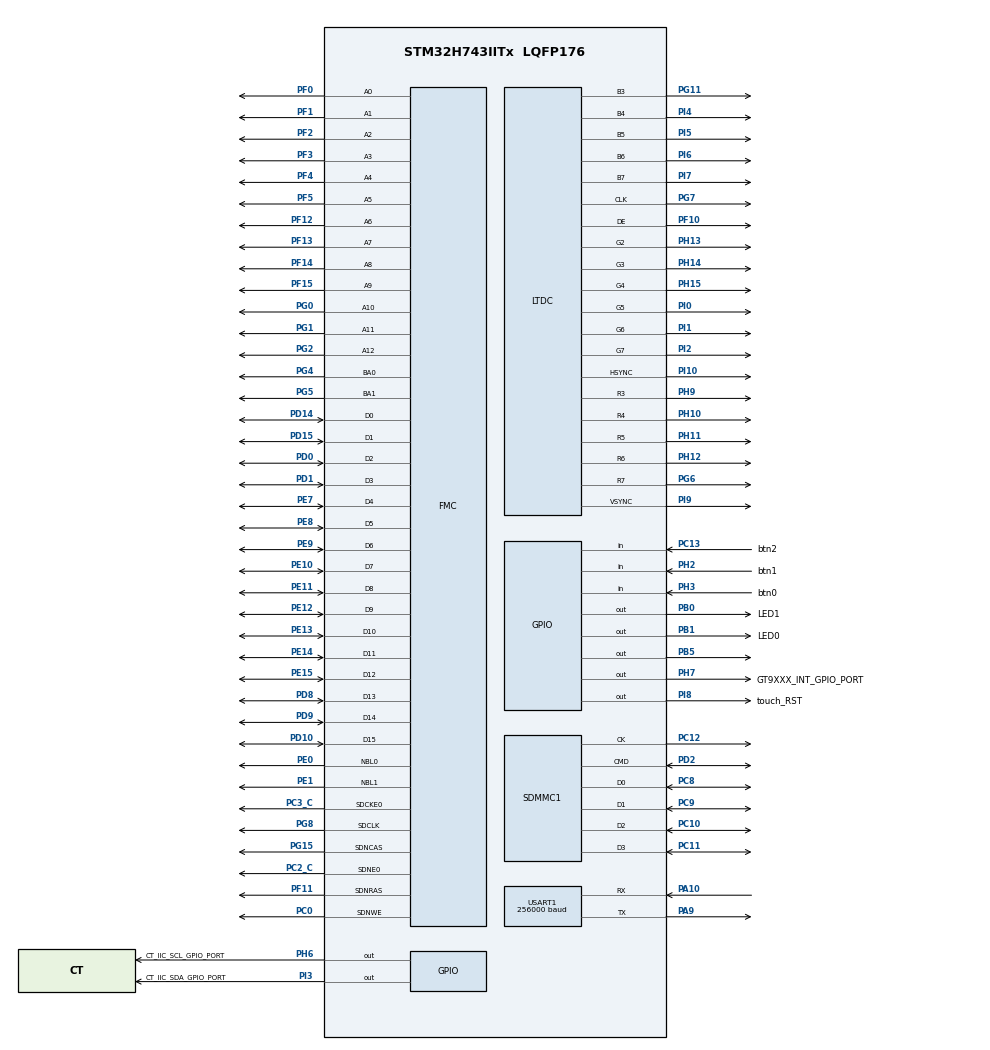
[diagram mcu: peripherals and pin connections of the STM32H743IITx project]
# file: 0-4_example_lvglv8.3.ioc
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CORTEX_M7.CPU_ICache=Disabled
CORTEX_M7.MPU_Control=__NULL
CORTEX_M7.default_mode_Activation=1
DMA2D.ColorMode=DMA2D_OUTPUT_RGB565
Dma.Request0=USART1_RX
Dma.Request1=USART1_TX
Dma.USART1_RX.0.Direction=DMA_PERIPH_TO_MEMORY
Dma.USART1_RX.0.EventEnable=DISABLE
Dma.USART1_RX.0.FIFOMode=DMA_FIFOMODE_DISABLE
Dma.USART1_RX.0.Instance=DMA1_Stream0
Dma.USART1_RX.0.MemDataAlignment=DMA_MDATAALIGN_BYTE
Dma.USART1_RX.0.MemInc=DMA_MINC_ENABLE
Dma.USART1_RX.0.Mode=DMA_NORMAL
Dma.USART1_RX.0.PeriphDataAlignment=DMA_PDATAALIGN_BYTE
Dma.USART1_RX.0.PeriphInc=DMA_PINC_DISABLE
Dma.USART1_RX.0.Polarity=HAL_DMAMUX_REQ_GEN_RISING
Dma.USART1_RX.0.Priority=DMA_PRIORITY_LOW
Dma.USART1_RX.0.RequestNumber=1
Dma.USART1_RX.0.SignalID=NONE
Dma.USART1_RX.0.SyncEnable=DISABLE
Dma.USART1_RX.0.SyncPolarity=HAL_DMAMUX_SYNC_NO_EVENT
Dma.USART1_RX.0.SyncRequestNumber=1
Dma.USART1_RX.0.SyncSignalID=NONE
Dma.USART1_TX.1.Direction=DMA_MEMORY_TO_PERIPH
Dma.USART1_TX.1.EventEnable=DISABLE
Dma.USART1_TX.1.FIFOMode=DMA_FIFOMODE_DISABLE
Dma.USART1_TX.1.Instance=DMA1_Stream1
Dma.USART1_TX.1.MemDataAlignment=DMA_MDATAALIGN_BYTE
Dma.USART1_TX.1.MemInc=DMA_MINC_ENABLE
Dma.USART1_TX.1.Mode=DMA_NORMAL
Dma.USART1_TX.1.PeriphDataAlignment=DMA_PDATAALIGN_BYTE
Dma.USART1_TX.1.PeriphInc=DMA_PINC_DISABLE
Dma.USART1_TX.1.Polarity=HAL_DMAMUX_REQ_GEN_RISING
Dma.USART1_TX.1.Priority=DMA_PRIORITY_LOW
Dma.USART1_TX.1.RequestNumber=1
Dma.USART1_TX.1.SignalID=NONE
Dma.USART1_TX.1.SyncEnable=DISABLE
Dma.USART1_TX.1.SyncPolarity=HAL_DMAMUX_SYNC_NO_EVENT
Dma.USART1_TX.1.SyncRequestNumber=1
Dma.USART1_TX.1.SyncSignalID=NONE
FATFS.USE_DMA_CODE_SD=1
FATFS._CODE_PAGE=936
FATFS._FS_EXFAT=1
FATFS._FS_RPATH=2
FATFS._LFN_UNICODE=1
FATFS._MAX_SS=4096
FATFS._USE_LFN=3
FATFS._USE_TRIM=1
FMC.CASLatency1=FMC_SDRAM_CAS_LATENCY_2
FMC.ColumnBitsNumber1=FMC_SDRAM_COLUMN_BITS_NUM_9
FMC.ExitSelfRefreshDelay1=8
FMC.LoadToActiveDelay1=2
FMC.RCDDelay1=2
FMC.RPDelay1=2
FMC.RPDelay2=2
FMC.ReadBurst1=FMC_SDRAM_RBURST_ENABLE
FMC.ReadBurst2=FMC_SDRAM_RBURST_ENABLE
FMC.ReadPipeDelay1=FMC_SDRAM_RPIPE_DELAY_1
FMC.ReadPipeDelay2=FMC_SDRAM_RPIPE_DELAY_1
FMC.RowCycleDelay1=6
FMC.RowCycleDelay2=6
FMC.SDClockPeriod1=FMC_SDRAM_CLOCK_PERIOD_2
FMC.SDClockPeriod2=FMC_SDRAM_CLOCK_PERIOD_2
FMC.SelfRefreshTime1=6
FMC.WriteRecoveryTime1=4
LTDC.ActiveW=800
LTDC.Alpha0_L0=0
LTDC.Alpha0_L1=0
LTDC.Alpha_L0=255
LTDC.Alpha_L1=255
LTDC.BlendingFactor1_L0=LTDC_BLENDING_FACTOR1_CA
LTDC.BlendingFactor1_L1=LTDC_BLENDING_FACTOR1_CA
LTDC.BlendingFactor2_L0=LTDC_BLENDING_FACTOR2_CA
LTDC.BlendingFactor2_L1=LTDC_BLENDING_FACTOR2_CA
LTDC.Blue=0
LTDC.Blue_L0=0
LTDC.Blue_L1=0
LTDC.FBStartAdress_L0=Layer0_Buffer
LTDC.FBStartAdress_L1=Layer1_Buffer
LTDC.Green=0
LTDC.Green_L0=0
LTDC.Green_L1=0
LTDC.HBP=88
LTDC.HFP=40
LTDC.HSync=48
LTDC.ImageHeight_L0=480
LTDC.ImageHeight_L1=480
LTDC.ImageWidth_L0=800
LTDC.Layers=0
LTDC.PCPolarity=LTDC_PCPOLARITY_IPC
LTDC.PixelFormat_L0=LTDC_PIXEL_FORMAT_RGB565
LTDC.Red=0
LTDC.Red_L0=0
LTDC.Red_L1=0
LTDC.VBP=32
LTDC.VFP=13
LTDC.VSync=3
LTDC.WindowX1_L0=800
LTDC.WindowX1_L1=800
LTDC.WindowY1_L0=480
LTDC.WindowY1_L1=480
Mcu.Family=STM32H7
Mcu.Name=STM32H743IITx
Mcu.Package=LQFP176
NVIC.DMA1_Stream0_IRQn=true\:0\:0\:false\:false\:true\:false\:true\:true
NVIC.DMA1_Stream1_IRQn=true\:0\:0\:false\:false\:true\:false\:true\:true
NVIC.DMA2D_IRQn=true\:1\:0\:true\:true\:true\:1\:true\:true\:true
NVIC.FMC_IRQn=true\:0\:0\:false\:false\:true\:true\:true\:true
NVIC.LTDC_ER_IRQn=true\:0\:0\:false\:false\:true\:true\:true\:true
NVIC.LTDC_IRQn=true\:0\:0\:false\:false\:true\:true\:true\:true
NVIC.PriorityGroup=NVIC_PRIORITYGROUP_4
NVIC.SDMMC1_IRQn=true\:1\:0\:true\:false\:true\:true\:true\:true
NVIC.TIM6_DAC_IRQn=true\:0\:0\:false\:false\:true\:true\:true\:true
NVIC.USART1_IRQn=true\:2\:0\:true\:false\:true\:true\:true\:true
PA10.Mode=Asynchronous
PA10.Signal=USART1_RX
PA13\ (JTMS/SWDIO).Mode=Serial_Wire
PA13\ (JTMS/SWDIO).Signal=DEBUG_JTMS-SWDIO
PA14\ (JTCK/SWCLK).Mode=Serial_Wire
PA14\ (JTCK/SWCLK).Signal=DEBUG_JTCK-SWCLK
PA9.Mode=Asynchronous
PA9.Signal=USART1_TX
PB0.GPIO_Label=LED1
PB0.GPIO_PuPd=GPIO_PULLUP
PB0.GPIO_Speed=GPIO_SPEED_FREQ_HIGH
PB0.PinState=GPIO_PIN_SET
PB0.Signal=GPIO_Output
PB1.GPIO_Label=LED0
PB1.GPIO_PuPd=GPIO_NOPULL
PB1.GPIO_Speed=GPIO_SPEED_FREQ_HIGH
PB1.Signal=GPIO_Output
PB5.PinState=GPIO_PIN_SET
PB5.Signal=GPIO_Output
PC0.Signal=FMC_SDNWE
PC10.Mode=SD_4_bits_Wide_bus
PC10.Signal=SDMMC1_D2
PC11.Mode=SD_4_bits_Wide_bus
PC11.Signal=SDMMC1_D3
PC12.Mode=SD_4_bits_Wide_bus
PC12.Signal=SDMMC1_CK
PC13.GPIO_Label=btn2
PC13.GPIO_PuPd=GPIO_PULLUP
PC13.Signal=GPIO_Input
PC14-OSC32_IN\ (OSC32_IN).Mode=LSE-External-Oscillator
PC14-OSC32_IN\ (OSC32_IN).Signal=RCC_OSC32_IN
PC15-OSC32_OUT\ (OSC32_OUT).Mode=LSE-External-Oscillator
PC15-OSC32_OUT\ (OSC32_OUT).Signal=RCC_OSC32_OUT
PC2_C.Mode=SdramChipSelect1_1
PC2_C.Signal=FMC_SDNE0
PC3_C.Mode=SdramChipSelect1_1
PC3_C.Signal=FMC_SDCKE0
PC8.Mode=SD_4_bits_Wide_bus
PC8.Signal=SDMMC1_D0
PC9.Mode=SD_4_bits_Wide_bus
PC9.Signal=SDMMC1_D1
PD0.Signal=FMC_D2_DA2
PD1.Signal=FMC_D3_DA3
PD10.Signal=FMC_D15_DA15
PD14.Signal=FMC_D0_DA0
PD15.Signal=FMC_D1_DA1
PD2.Mode=SD_4_bits_Wide_bus
PD2.Signal=SDMMC1_CMD
PD8.Signal=FMC_D13_DA13
PD9.Signal=FMC_D14_DA14
PE0.Signal=FMC_NBL0
PE1.Signal=FMC_NBL1
PE10.Signal=FMC_D7_DA7
PE11.Signal=FMC_D8_DA8
PE12.Signal=FMC_D9_DA9
PE13.Signal=FMC_D10_DA10
PE14.Signal=FMC_D11_DA11
PE15.Signal=FMC_D12_DA12
PE7.Signal=FMC_D4_DA4
PE8.Signal=FMC_D5_DA5
PE9.Signal=FMC_D6_DA6
PF0.Signal=FMC_A0
PF1.Signal=FMC_A1
PF10.GPIO_Speed=GPIO_SPEED_FREQ_VERY_HIGH
PF10.Mode=RGB565
PF10.Signal=LTDC_DE
PF11.Signal=FMC_SDNRAS
PF12.Signal=FMC_A6
PF13.Signal=FMC_A7
PF14.Signal=FMC_A8
PF15.Signal=FMC_A9
PF2.Signal=FMC_A2
PF3.Signal=FMC_A3
PF4.Signal=FMC_A4
PF5.Signal=FMC_A5
PG0.Signal=FMC_A10
PG1.Signal=FMC_A11
PG11.GPIO_Speed=GPIO_SPEED_FREQ_VERY_HIGH
PG11.Mode=RGB565
PG11.Signal=LTDC_B3
PG15.Signal=FMC_SDNCAS
PG2.Signal=FMC_A12
PG4.Signal=FMC_A14_BA0
PG5.Signal=FMC_A15_BA1
PG6.GPIO_Speed=GPIO_SPEED_FREQ_VERY_HIGH
PG6.Mode=RGB565
PG6.Signal=LTDC_R7
PG7.GPIO_Speed=GPIO_SPEED_FREQ_VERY_HIGH
PG7.Mode=RGB565
PG7.Signal=LTDC_CLK
PG8.Signal=FMC_SDCLK
PH0-OSC_IN\ (PH0).Mode=HSE-External-Oscillator
PH0-OSC_IN\ (PH0).Signal=RCC_OSC_IN
PH1-OSC_OUT\ (PH1).Mode=HSE-External-Oscillator
PH1-OSC_OUT\ (PH1).Signal=RCC_OSC_OUT
PH10.GPIO_Speed=GPIO_SPEED_FREQ_VERY_HIGH
PH10.Mode=RGB565
PH10.Signal=LTDC_R4
PH11.GPIO_Speed=GPIO_SPEED_FREQ_VERY_HIGH
PH11.Mode=RGB565
PH11.Signal=LTDC_R5
PH12.GPIO_Speed=GPIO_SPEED_FREQ_VERY_HIGH
PH12.Mode=RGB565
PH12.Signal=LTDC_R6
PH13.GPIO_Speed=GPIO_SPEED_FREQ_VERY_HIGH
PH13.Mode=RGB565
PH13.Signal=LTDC_G2
PH14.GPIO_Speed=GPIO_SPEED_FREQ_VERY_HIGH
PH14.Mode=RGB565
PH14.Signal=LTDC_G3
PH15.GPIO_Speed=GPIO_SPEED_FREQ_VERY_HIGH
PH15.Mode=RGB565
PH15.Signal=LTDC_G4
PH2.GPIO_Label=btn1
PH2.GPIO_PuPd=GPIO_PULLUP
PH2.Signal=GPIO_Input
PH3.GPIO_Label=btn0
PH3.GPIO_PuPd=GPIO_PULLUP
PH3.Signal=GPIO_Input
PH6.GPIO_Label=CT_IIC_SCL_GPIO_PORT
PH6.GPIO_ModeDefaultOutputPP=GPIO_MODE_OUTPUT_PP
PH6.GPIO_PuPd=GPIO_PULLUP
PH6.GPIO_Speed=GPIO_SPEED_FREQ_HIGH
PH6.PinState=GPIO_PIN_RESET
PH6.Signal=GPIO_Output
PH7.GPIO_Label=GT9XXX_INT_GPIO_PORT
PH7.GPIO_Speed=GPIO_SPEED_FREQ_HIGH
PH7.Signal=GPIO_Output
PH9.GPIO_Speed=GPIO_SPEED_FREQ_VERY_HIGH
PH9.Mode=RGB565
PH9.Signal=LTDC_R3
PI0.GPIO_Speed=GPIO_SPEED_FREQ_VERY_HIGH
PI0.Mode=RGB565
PI0.Signal=LTDC_G5
PI1.GPIO_Speed=GPIO_SPEED_FREQ_VERY_HIGH
PI1.Mode=RGB565
PI1.Signal=LTDC_G6
PI10.GPIO_Speed=GPIO_SPEED_FREQ_VERY_HIGH
PI10.Mode=RGB565
PI10.Signal=LTDC_HSYNC
PI2.GPIO_Speed=GPIO_SPEED_FREQ_VERY_HIGH
PI2.Mode=RGB565
PI2.Signal=LTDC_G7
PI3.GPIO_Label=CT_IIC_SDA_GPIO_PORT
PI3.GPIO_PuPd=GPIO_PULLUP
PI3.GPIO_Speed=GPIO_SPEED_FREQ_HIGH
PI3.PinState=GPIO_PIN_RESET
PI3.Signal=GPIO_Output
PI4.GPIO_Speed=GPIO_SPEED_FREQ_VERY_HIGH
PI4.Mode=RGB565
PI4.Signal=LTDC_B4
PI5.GPIO_Speed=GPIO_SPEED_FREQ_VERY_HIGH
PI5.Mode=RGB565
PI5.Signal=LTDC_B5
PI6.GPIO_Speed=GPIO_SPEED_FREQ_VERY_HIGH
PI6.Mode=RGB565
PI6.Signal=LTDC_B6
PI7.GPIO_Speed=GPIO_SPEED_FREQ_VERY_HIGH
PI7.Mode=RGB565
PI7.Signal=LTDC_B7
PI8.GPIO_Label=touch_RST
PI8.Signal=GPIO_Output
PI9.GPIO_Speed=GPIO_SPEED_FREQ_VERY_HIGH
PI9.Mode=RGB565
PI9.Signal=LTDC_VSYNC
ProjectManager.HeapSize=0x1200
ProjectManager.StackSize=0x1200
ProjectManager.TargetToolchain=STM32CubeIDE
RCC.ADCFreq_Value=480000000
RCC.APB1Freq_Value=120000000
RCC.APB2Freq_Value=120000000
RCC.APB3Freq_Value=120000000
RCC.APB4Freq_Value=120000000
RCC.CortexFreq_Value=480000000
RCC.D1PPRE=RCC_APB3_DIV2
RCC.D2PPRE1=RCC_APB1_DIV2
RCC.D2PPRE2=RCC_APB2_DIV2
RCC.D3PPRE=RCC_APB4_DIV2
RCC.DIVM1=5
RCC.DIVM2=5
RCC.DIVM3=25
RCC.DIVN1=192
RCC.DIVN2=192
RCC.DIVN3=396
RCC.DIVQ1=4
RCC.DIVQ2=4
RCC.DIVR2=4
RCC.DIVR3=9
RCC.HCLKFreq_Value=240000000
RCC.HPRE=RCC_HCLK_DIV2
RCC.PLLSourceVirtual=RCC_PLLSOURCE_HSE
RCC.RTCClockSelection=RCC_RTCCLKSOURCE_LSE
RCC.SYSCLKFreq_VALUE=480000000
RCC.SYSCLKSource=RCC_SYSCLKSOURCE_PLLCLK
RCC.USBFreq_Value=240000000
RTC.Date=3
RTC.Format=RTC_FORMAT_BIN
RTC.Hours=3
RTC.Minutes=3
RTC.Seconds=3
RTC.Year=3
SDMMC1.ClockDiv=8
SH.FMC_A0.0=FMC_A0,13b-sda1
SH.FMC_A1.0=FMC_A1,13b-sda1
SH.FMC_A10.0=FMC_A10,13b-sda1
SH.FMC_A11.0=FMC_A11,13b-sda1
SH.FMC_A12.0=FMC_A12,13b-sda1
SH.FMC_A14_BA0.0=FMC_BA0,FourSdramBanks1
SH.FMC_A15_BA1.0=FMC_BA1,FourSdramBanks1
SH.FMC_A2.0=FMC_A2,13b-sda1
SH.FMC_A3.0=FMC_A3,13b-sda1
SH.FMC_A4.0=FMC_A4,13b-sda1
SH.FMC_A5.0=FMC_A5,13b-sda1
SH.FMC_A6.0=FMC_A6,13b-sda1
SH.FMC_A7.0=FMC_A7,13b-sda1
SH.FMC_A8.0=FMC_A8,13b-sda1
SH.FMC_A9.0=FMC_A9,13b-sda1
SH.FMC_D0_DA0.0=FMC_D0,sd-16b-d1
SH.FMC_D10_DA10.0=FMC_D10,sd-16b-d1
SH.FMC_D11_DA11.0=FMC_D11,sd-16b-d1
SH.FMC_D12_DA12.0=FMC_D12,sd-16b-d1
SH.FMC_D13_DA13.0=FMC_D13,sd-16b-d1
SH.FMC_D14_DA14.0=FMC_D14,sd-16b-d1
SH.FMC_D15_DA15.0=FMC_D15,sd-16b-d1
SH.FMC_D1_DA1.0=FMC_D1,sd-16b-d1
SH.FMC_D2_DA2.0=FMC_D2,sd-16b-d1
SH.FMC_D3_DA3.0=FMC_D3,sd-16b-d1
SH.FMC_D4_DA4.0=FMC_D4,sd-16b-d1
SH.FMC_D5_DA5.0=FMC_D5,sd-16b-d1
SH.FMC_D6_DA6.0=FMC_D6,sd-16b-d1
SH.FMC_D7_DA7.0=FMC_D7,sd-16b-d1
SH.FMC_D8_DA8.0=FMC_D8,sd-16b-d1
SH.FMC_D9_DA9.0=FMC_D9,sd-16b-d1
SH.FMC_NBL0.0=FMC_NBL0,Sd2ByteEnable1
SH.FMC_NBL1.0=FMC_NBL1,Sd2ByteEnable1
SH.FMC_SDCLK.0=FMC_SDCLK,13b-sda1
SH.FMC_SDNCAS.0=FMC_SDNCAS,13b-sda1
SH.FMC_SDNRAS.0=FMC_SDNRAS,13b-sda1
SH.FMC_SDNWE.0=FMC_SDNWE,13b-sda1
TIM6.AutoReloadPreload=TIM_AUTORELOAD_PRELOAD_ENABLE
TIM6.Period=100-1
TIM6.Prescaler=2400-1
USART1.BaudRate=256000
USART1.VirtualMode-Asynchronous=VM_ASYNC
VP_DMA2D_VS_DMA2D.Mode=DMA2D_Activate
VP_FATFS_VS_SDIO.Mode=SDIO
VP_MEMORYMAP_VS_MEMORYMAP.Mode=CurAppReg
VP_RTC_VS_RTC_Activate.Mode=RTC_Enabled
VP_RTC_VS_RTC_Calendar.Mode=RTC_Calendar
VP_TIM6_VS_ClockSourceINT.Mode=Enable_Timer
board=custom

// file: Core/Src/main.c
/* USER CODE BEGIN Header */
/**
  ******************************************************************************
  * @file           : main.c
  * @brief          : Main program body
  ******************************************************************************
  * @attention
  *
  * Copyright (c) 2025 STMicroelectronics.
  * All rights reserved.
  *
  *
  * 此工程调通: FMC(sdram), ltdc显示屏, dma2d, 触摸屏, sdmmc(SD卡), printf(uart1), 事件按钮, fatFS文件系统, lvgl图形界面
  *
  *
  ******************************************************************************
  */
/* USER CODE END Header */
#include "main.h"
#include "dma.h"
#include "dma2d.h"
#include "fatfs.h"
#include "ltdc.h"
#include "rtc.h"
#include "sdmmc.h"
#include "tim.h"
#include "usart.h"
#include "gpio.h"
#include "fmc.h"

/* USER CODE BEGIN Includes */
//#define NDEBUG
#include "string.h"
#include "sys.h"
#include "delay.h"
#include "usart/retarget.h"
//BSP
#include "sdram/W9825G6KH.h"
#include "MALLOC/malloc.h"
#include "rgbLCD/LCD.h"
#include "touch_GT9147/touch_gt9xxx.h"
#include "key/Button_event.h"
//Middlewares
#include "lvgl.h"                // 它为整个LVGL提供了更完整的头文件引用
#include "lv_port_disp.h"        // LVGL的显示支持
#include "lv_port_indev.h"       // LVGL的触屏支持
#include "lv_conf.h"
//APP
#include "SDRAM_test/sdram_test.h"		//SDRAM基本读写测试
#include "RAMspeed_test/speed_test.h"	//melloc测试不同ram区速度
#include "SDCARD_test/SDCARD_test.h"	//SD卡基本读写测试
#include "FATFS_test/FATFS_test.h"		//fatfs文件系统测试
#include "LVGL_test/LVGL_test.h"		//LVGL文件系统测试
//lvgl_app
#include "benchmark/lv_demo_benchmark.h"
#include "ui/Act_Manager.h"		//ui界面

/* USER CODE END Includes */

/* USER CODE BEGIN PV */
char receivData[50] = {0};	//存放串口接收内容(记得初始化)
uint8_t dataReady = 0;		//发送标志位

/* USER CODE END PV */

void SystemClock_Config(void);
static void MX_NVIC_Init(void);
/* USER CODE BEGIN PFP */

//重定义'串口事件回调'函数
void HAL_UARTEx_RxEventCallback(UART_HandleTypeDef *huart, uint16_t Size){
	if(huart == &huart1){
		dataReady = 1;//在主函数里处理发送
		HAL_UARTEx_ReceiveToIdle_DMA(&huart1, (uint8_t*)receivData, 50);//重新开启接收
	}
}

//重定义'定时时间到'
void HAL_TIM_PeriodElapsedCallback(TIM_HandleTypeDef *htim){
	static uint16_t Times6 = 0;
	if (htim->Instance == TIM6){

		lv_tick_inc(1);	//给lvgl提供时基

		Times6++;
		if(Times6 >= 500){
			HAL_GPIO_TogglePin(LED0_GPIO_Port, LED0_Pin);//led闪烁指示
			Times6 = 0;
		}
	}

}
/* USER CODE END PFP */

/* USER CODE BEGIN 0 */

#define usart1_echo			1
#define sdram_base_test		0
#define memory_speed_test	0	//malloc
#define fatfs_base_test		0	//直接操作fatfs
#define lvgl_base_test		0	//lvgl基本显示测试
#define lvgl_ui_test		0	//ui测试

/* USER CODE END 0 */

int main(void)
{

  /* MCU Configuration--------------------------------------------------------*/

  /* Reset of all peripherals, Initializes the Flash interface and the Systick. */
  HAL_Init();

  /* Configure the system clock */
  SystemClock_Config();

  /* USER CODE BEGIN SysInit */
  delay_init(480);								//自定义延时初始化
  /* USER CODE END SysInit */

  /* Initialize all configured peripherals */
  MX_GPIO_Init();
  MX_DMA_Init();
  MX_USART1_UART_Init();
  MX_FMC_Init();
  MX_LTDC_Init();
  MX_DMA2D_Init();
  MX_TIM6_Init();
  MX_SDMMC1_SD_Init();
  MX_FATFS_Init();
  MX_RTC_Init();

  /* Initialize interrupts */
  MX_NVIC_Init();
  /* USER CODE BEGIN 2 */

  Button_Init();								//按钮初始化(这个还没有加入到lvgl组)
  RetargetInit(&huart1);						//绑定printf使用的串口
#if usart1_echo
  HAL_UARTEx_ReceiveToIdle_DMA(&huart1, (uint8_t*)receivData, 50);//开启接收
#endif
#ifndef NDEBUG
  printf("printf init success!!\r\n");
#endif
  SDRAM_InitSequence();							//外部SDRAM初始化

#if  sdram_base_test
  fsmc_sdram_test();			//sdram基本读写测试
#endif

  HAL_Delay(100);								//内存池初始化
  my_mem_init(SRAMIN);							//D1域
  my_mem_init(SRAMEX);							//外部SDRAM
  my_mem_init(SRAM12);							//D2域
  my_mem_init(SRAM4);							//D3域
  my_mem_init(SRAMDTCM);						//DTCM
  my_mem_init(SRAMITCM);						//ITCM
#ifndef NDEBUG
  printf("mallco init success!!\r\n");
#endif
#if  sdram_base_test
  memory_speed_test_all();		//内存速度测试
#endif
/* ================================ fatFS ===================================== */
#if  fatfs_base_test
    fatfs_test();				//文件系统测试
#endif

/* ================================= LVGL初始化 ===================================== */
    lv_init();                             		// LVGL 初始化
    lv_port_disp_init();                   		// 注册LVGL的显示任务
    lv_port_indev_init();                  		// 注册LVGL的触屏检测任务
    HAL_TIM_Base_Start_IT(&htim6);				//开启lvgl时基
/* ================================================================================= */

/* ==================================== ui ========================================= */
#if LV_USE_DEMO_BENCHMARK
    lv_demo_benchmark();
#endif

#if lvgl_base_test
    lvgl_basic_test();			//lvgl基本显示测试
#endif
#if lvgl_ui_test
    act_manager_init();
#endif
/* ================================================================================= */
  /* USER CODE END 2 */

  /* Infinite loop */
  /* USER CODE BEGIN WHILE */
  while (1)
  {
#if usart1_echo
	if (dataReady) {HAL_UART_Transmit_DMA(&huart1, (uint8_t *) receivData, strlen(receivData));dataReady = 0;}//回显
#endif

	lv_timer_handler();
	HAL_Delay(5);

    /* USER CODE END WHILE */

  }
}

void SystemClock_Config(void)
{
  RCC_OscInitTypeDef RCC_OscInitStruct = {0};
  RCC_ClkInitTypeDef RCC_ClkInitStruct = {0};

  /** Supply configuration update enable
  */
  HAL_PWREx_ConfigSupply(PWR_LDO_SUPPLY);

  /** Configure the main internal regulator output voltage
  */
  __HAL_PWR_VOLTAGESCALING_CONFIG(PWR_REGULATOR_VOLTAGE_SCALE0);

  while(!__HAL_PWR_GET_FLAG(PWR_FLAG_VOSRDY)) {}

  /** Configure LSE Drive Capability
  */
  HAL_PWR_EnableBkUpAccess();
  __HAL_RCC_LSEDRIVE_CONFIG(RCC_LSEDRIVE_LOW);

  /** Initializes the RCC Oscillators according to the specified parameters
  * in the RCC_OscInitTypeDef structure.
  */
  RCC_OscInitStruct.OscillatorType = RCC_OSCILLATORTYPE_HSE|RCC_OSCILLATORTYPE_LSE;
  RCC_OscInitStruct.HSEState = RCC_HSE_ON;
  RCC_OscInitStruct.LSEState = RCC_LSE_ON;
  RCC_OscInitStruct.PLL.PLLState = RCC_PLL_ON;
  RCC_OscInitStruct.PLL.PLLSource = RCC_PLLSOURCE_HSE;
  RCC_OscInitStruct.PLL.PLLM = 5;
  RCC_OscInitStruct.PLL.PLLN = 192;
  RCC_OscInitStruct.PLL.PLLP = 2;
  RCC_OscInitStruct.PLL.PLLQ = 4;
  RCC_OscInitStruct.PLL.PLLR = 2;
  RCC_OscInitStruct.PLL.PLLRGE = RCC_PLL1VCIRANGE_2;
  RCC_OscInitStruct.PLL.PLLVCOSEL = RCC_PLL1VCOWIDE;
  RCC_OscInitStruct.PLL.PLLFRACN = 0;
  if (HAL_RCC_OscConfig(&RCC_OscInitStruct) != HAL_OK)
  {
    Error_Handler();
  }

  /** Initializes the CPU, AHB and APB buses clocks
  */
  RCC_ClkInitStruct.ClockType = RCC_CLOCKTYPE_HCLK|RCC_CLOCKTYPE_SYSCLK
                              |RCC_CLOCKTYPE_PCLK1|RCC_CLOCKTYPE_PCLK2
                              |RCC_CLOCKTYPE_D3PCLK1|RCC_CLOCKTYPE_D1PCLK1;
  RCC_ClkInitStruct.SYSCLKSource = RCC_SYSCLKSOURCE_PLLCLK;
  RCC_ClkInitStruct.SYSCLKDivider = RCC_SYSCLK_DIV1;
  RCC_ClkInitStruct.AHBCLKDivider = RCC_HCLK_DIV2;
  RCC_ClkInitStruct.APB3CLKDivider = RCC_APB3_DIV2;
  RCC_ClkInitStruct.APB1CLKDivider = RCC_APB1_DIV2;
  RCC_ClkInitStruct.APB2CLKDivider = RCC_APB2_DIV2;
  RCC_ClkInitStruct.APB4CLKDivider = RCC_APB4_DIV2;

  if (HAL_RCC_ClockConfig(&RCC_ClkInitStruct, FLASH_LATENCY_4) != HAL_OK)
  {
    Error_Handler();
  }
}

/**
  * @brief NVIC Configuration.
  * @retval None
  */
static void MX_NVIC_Init(void)
{
  /* DMA2D_IRQn interrupt configuration */
  HAL_NVIC_SetPriority(DMA2D_IRQn, 1, 0);
  HAL_NVIC_EnableIRQ(DMA2D_IRQn);
}

void Error_Handler(void)
{
  __disable_irq();
  while (1)
  {
  }
}
